# YTM32B1LE1 register map
Vendor: YTMicro; File version: 1.0
CPU: CM0PLUS r0p1, little endian, MPU, FPU, 2 interrupt priority bits
Registers are 32-bit, read-write, reset 0x0 unless marked. A register's access mark holds for its fields unless they carry their own. Offsets are from the block's base; [hi:lo] are bit positions.

## CIM — Chip Integration Module of Microcontroller
Base 0x40048000; register names take the prefix CIM_
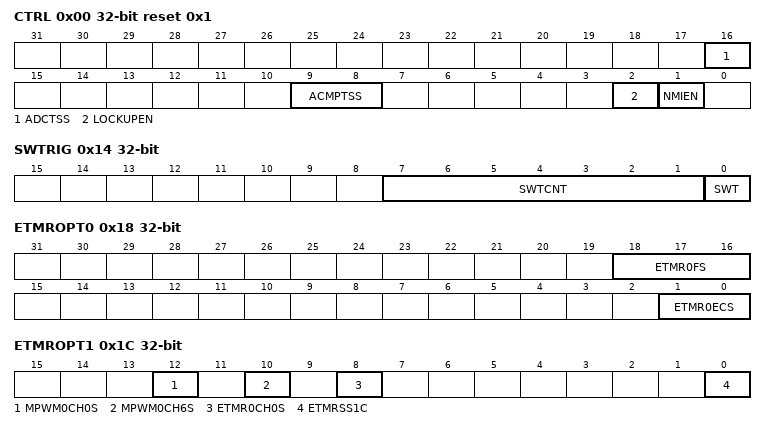
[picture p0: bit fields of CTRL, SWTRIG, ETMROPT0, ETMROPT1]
0x00 CTRL reset 0x1
  [16] ADCTSS — Select ADC input trigger synchronized mode.
    0=Input trigger is synchronized signal, synchronized by bus clock; 1=Input trigger is synchronized signal, synchronized by functional clock
  [9:8] ACMPTSS — Select ACMP input trigger synchronized mode.
    0=Input trigger is raw signal; 1=Input trigger is synchronized signal, synchronized by bus clock; 2=Input trigger is synchronized signal, synchronized by functional clock
  [2] LOCKUPEN — Enable CPU Lockup Reset.
    0=CPU Lockup reset is disabled; 1=CPU Lockup reset is enabled
  [1] NMIEN — Enable NMI function.
    0=NMI is disabled; 1=NMI is enabled
0x14 SWTRIG
  [7:1] SWTCNT — Define software trigger valid length (multiplied with bus clock cycle), SWTCNT value will decrease until equal to zero when SWT set.
  [0] SWT — Generate software trigger.
    0=Software trigger is disabled; 1=Generate software trigger and it keeps until SWTCNT equals to zero
0x18 ETMROPT0
  [18:16] ETMR0FS — Select fault source for ETMR0. xx0b - ETMR0 fault 0 input from pad. xx1b - ETMR0 fault 0 input from TMU. x0xb - ETMR0 fault 1 input from pad. x1xb - ETMR0 fault 1 input from TMU. 0xxb - ETMR0 fault 2 input from pad. 1xxb - ETMR0 fault 2 input from TMU.
  [1:0] ETMR0ECS — Select external clock source for ETMR0.
    0=Select TCLK_IN0 input as external clock for ETMR0; 1=Select TCLK_IN1 input as external clock for ETMR0; 2=Select TCLK_IN2 input as external clock for ETMR0; 3=Select IPC function clock as external clock for ETMR0
0x1C ETMROPT1
  [12] MPWM0CH0S — Select input source for MPWM0 channel 0.
    0=MPWM0 channel 0 input from pad; 1=MPWM0 channel 0 input from XOR result(MPWM0_CH0, MPWM0_CH3, MPWM0_CH5)
  [10] MPWM0CH6S — Select input source for MPWM0 channel 6.
    0=MWPM0 channel 6 input from pad; 1=MPWM0 channel 6 input from ACMP out
  [8] ETMR0CH0S — Select input source for ETMR0 channel 0.
    0=ETMR0 channel 0 input from pad; 1=ETMR0 channel 0 input from ACMP out
  [0] ETMRSS1C — Generate synchronize signal for ETMR trigger 1. 0b - Don't generate synchronize signal for ETMR0 trigger 1. 1b - Generate synchronize signal for ETMR0 trigger 1.
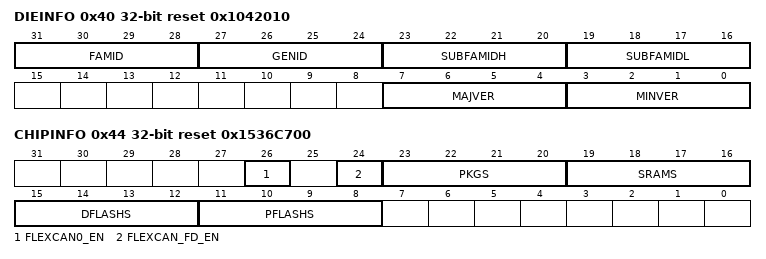
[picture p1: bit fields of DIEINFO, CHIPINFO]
0x40 DIEINFO ro reset 0x1042010
  [31:28] FAMID — Describe the product family information.
    0=B - Basic(General); 1=D - Dashboard; 2=P - Powertrain; 3=V - Vision; 4=N - Networks
  [27:24] GENID — Describe the product generation information.
    1=1st generation production; 2=2nd generation production; 3=3rd generation production
  [23:20] SUBFAMIDH — Describe the product sub family information.
    0=L - Low end; 1=M - Middle end; 2=H - High end
  [19:16] SUBFAMIDL — Describe the product max Flash size information.
    0=A - 8KB; 1=B - 16KB; 2=C - 32KB; 3=D - 64KB; 4=E - 128KB
  [7:4] MAJVER — Describe the major version information.
  [3:0] MINVER — Describe the minor version information.
0x44 CHIPINFO ro reset 0x1536C700
  [26] FLEXCAN0_EN — FlexCAN0 Enable/Disable
    0=FlexCAN0 is disabled; 1=FlexCAN0 is enable
  [24] FLEXCAN_FD_EN — FlexCAN FD Feature Enable/Disable
    0=FlexCAN FD Feature is disabled; 1=FlexCAN FD Feature is enable
  [23:20] PKGS — Describe chip package type information.
    1=20 TSSOP; 2=32 QFN; 3=48 LQFP/QFN
  [19:16] SRAMS — Describe sram size information. NOTE: this field indicates TCML or TCMU size (SRAM size divided by 2).
    2=1KB; 3=2KB; 4=4KB; 5=8KB; 6=16KB
  [15:12] DFLASHS — Describe data flash size information.
    12=12KB
  [11:8] PFLASHS — Describe program flash size information.
    0=1KB; 1=2KB; 2=4KB; 3=8KB; 4=16KB; 5=32KB; 6=64KB; 7=128KB
